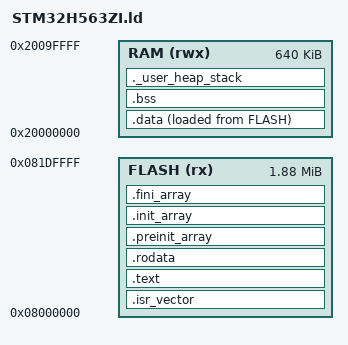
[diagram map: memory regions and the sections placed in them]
/* STM32H563ZI Linker Script (TrustZone disabled)
 *
 * Copyright (C) 2006-2025 wolfSSL Inc.
 *
 * This file is part of wolfTPM.
 *
 * wolfTPM is free software; you can redistribute it and/or modify
 * it under the terms of the GNU General Public License as published by
 * the Free Software Foundation; either version 3 of the License, or
 * (at your option) any later version.
 *
 * wolfTPM is distributed in the hope that it will be useful,
 * but WITHOUT ANY WARRANTY; without even the implied warranty of
 * MERCHANTABILITY or FITNESS FOR A PARTICULAR PURPOSE.  See the
 * GNU General Public License for more details.
 *
 * You should have received a copy of the GNU General Public License
 * along with this program; if not, write to the Free Software
 * Foundation, Inc., 51 Franklin Street, Fifth Floor, Boston, MA 02110-1335, USA
 *
 * Memory Map (TZEN=0):
 *   FLASH: 2048KB @ 0x08000000 (minus 128KB NV = 1920KB code)
 *   SRAM:  640KB @ 0x20000000 (contiguous SRAM1+SRAM2+SRAM3)
 *
 * NV flash storage: last 128KB (0x081E0000 - 0x081FFFFF)
 */

ENTRY(Reset_Handler)

_estack = ORIGIN(RAM) + LENGTH(RAM);
_sidata = LOADADDR(.data);

_Min_Heap_Size  = 0x30000;  /* 192KB heap for FWTPM_CTX + wolfCrypt */
_Min_Stack_Size = 0x10000;  /* 64KB stack (RSA keygen needs headroom) */

MEMORY
{
  FLASH (rx)  : ORIGIN = 0x08000000, LENGTH = 1920K
  RAM   (rwx) : ORIGIN = 0x20000000, LENGTH = 640K
}

SECTIONS
{
  .isr_vector :
  {
    . = ALIGN(4);
    KEEP(*(.isr_vector))
    . = ALIGN(4);
  } > FLASH

  .text :
  {
    . = ALIGN(4);
    *(.text)
    *(.text*)
    *(.glue_7)
    *(.glue_7t)
    *(.eh_frame)
    *(.ARM.extab* .gnu.linkonce.armextab.*)
    *(.ARM.exidx* .gnu.linkonce.armexidx.*)

    KEEP (*(.init))
    KEEP (*(.fini))

    . = ALIGN(4);
    _etext = .;
  } > FLASH

  .rodata :
  {
    . = ALIGN(4);
    *(.rodata)
    *(.rodata*)
    . = ALIGN(4);
  } > FLASH

  .preinit_array :
  {
    __preinit_array_start = .;
    KEEP(*(.preinit_array*))
    __preinit_array_end = .;
  } > FLASH

  .init_array :
  {
    __init_array_start = .;
    KEEP(*(SORT(.init_array.*)))
    KEEP(*(.init_array*))
    __init_array_end = .;
  } > FLASH

  .fini_array :
  {
    __fini_array_start = .;
    KEEP(*(SORT(.fini_array.*)))
    KEEP(*(.fini_array*))
    __fini_array_end = .;
  } > FLASH

  .data :
  {
    . = ALIGN(4);
    _sdata = .;
    *(.data)
    *(.data*)
    *(.RamFunc)
    *(.RamFunc*)

    . = ALIGN(4);
    _edata = .;
  } > RAM AT> FLASH

  .bss (NOLOAD) :
  {
    _sbss = .;
    __bss_start__ = _sbss;
    *(.bss)
    *(.bss*)
    *(COMMON)

    . = ALIGN(4);
    _ebss = .;
    __bss_end__ = _ebss;
  } > RAM

  ._user_heap_stack (NOLOAD) :
  {
    . = ALIGN(8);
    PROVIDE ( end = . );
    PROVIDE ( _end = . );
    . = . + _Min_Heap_Size;
    . = . + _Min_Stack_Size;
    . = ALIGN(8);
  } > RAM

  /DISCARD/ :
  {
    libc.a ( * )
    libm.a ( * )
    libgcc.a ( * )
  }

  .ARM.attributes 0 : { *(.ARM.attributes) }
}
